VERSION "3.06 v1"

NS_ :

BS_:

BU_:

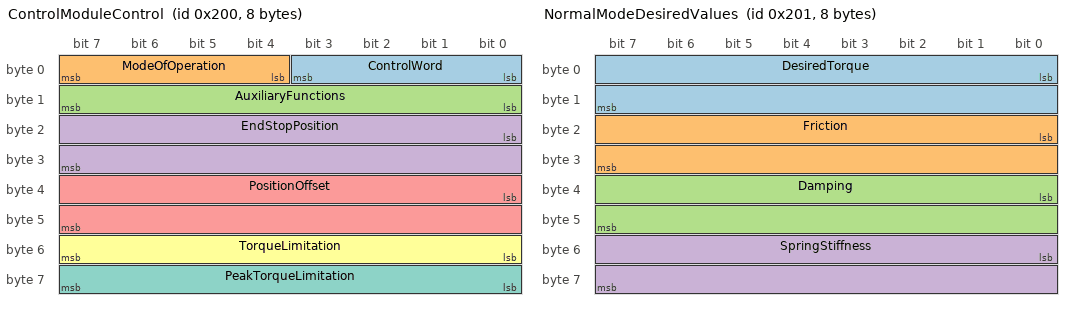
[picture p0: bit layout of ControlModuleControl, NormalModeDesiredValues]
BO_ 512 ControlModuleControl: 8 Vector__XXX
 SG_ ControlWord : 0|4@1+ (1,0) [0|15] "" Vector__XXX
 SG_ ModeOfOperation : 4|4@1+ (1,0) [1|8] "" Vector__XXX
 SG_ AuxiliaryFunctions : 8|8@1+ (1,0) [0|255] "" Vector__XXX
 SG_ EndStopPosition : 16|16@1+ (1,0) [0|1440] "°" Vector__XXX
 SG_ PositionOffset : 32|16@1- (1,0) [-359|359] "°" Vector__XXX
 SG_ TorqueLimitation : 48|8@1+ (1,0) [0|255] "%" Vector__XXX
 SG_ PeakTorqueLimitation : 56|8@1+ (1,0) [0|100] "%" Vector__XXX

BO_ 513 NormalModeDesiredValues: 8 Vector__XXX
 SG_ DesiredTorque : 0|16@1- (0.001,0) [-32.768|32.767] "Nm" Vector__XXX
 SG_ Friction : 16|16@1+ (1,0) [0|5000] "mNm" Vector__XXX
 SG_ Damping : 32|16@1+ (1,0) [0|500] "mNm/rpm" Vector__XXX
 SG_ SpringStiffness : 48|16@1+ (1,0) [0|2500] "mNm/°" Vector__XXX

BO_ 514 BasicModeDesiredValues: 2 Vector__XXX
 SG_ DesiredTorque : 0|16@1- (0.001,0) [-32.768|32.767] "Nm" Vector__XXX

BO_ 522 DigitalOutputValues: 2 Vector__XXX
 SG_ DigitalOutput : 0|3@1+ (1,0) [0|7] "" Vector__XXX

BO_ 523 AbsolutePosition: 2 Vector__XXX
 SG_ AbsolutePosition : 0|16@1- (0.1,0) [-1440|1440] "°" Vector__XXX

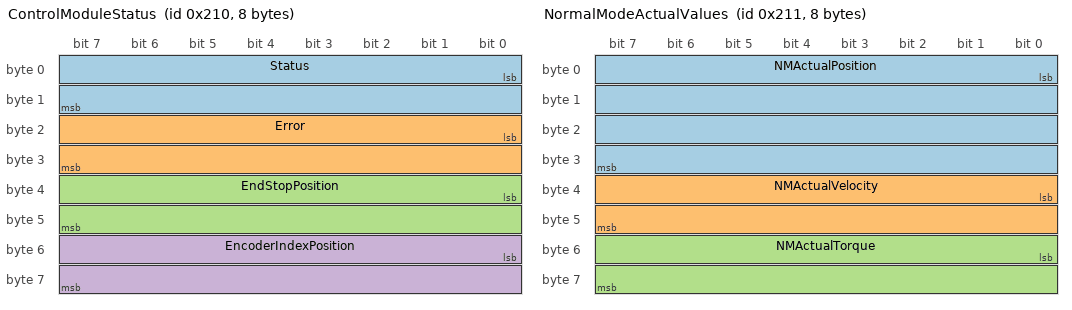
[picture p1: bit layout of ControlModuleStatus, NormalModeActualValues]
BO_ 528 ControlModuleStatus: 8 Vector__XXX
 SG_ Status : 0|16@1+ (1,0) [0|65535] "" Vector__XXX
 SG_ Error : 16|16@1+ (1,0) [0|65535] "" Vector__XXX
 SG_ EndStopPosition : 32|16@1+ (1,0) [0|1440] "°" Vector__XXX
 SG_ EncoderIndexPosition : 48|16@1- (1,0) [-359|359] "°" Vector__XXX

BO_ 529 NormalModeActualValues: 8 Vector__XXX
 SG_ NMActualPosition : 0|32@1- (1,0) [-2147483648|2147483647] "inc" Vector__XXX
 SG_ NMActualVelocity : 32|16@1- (1,0) [-32768|32767] "rpm" Vector__XXX
 SG_ NMActualTorque : 48|16@1- (0.001,0) [-32.768|32.767] "Nm" Vector__XXX

BO_ 530 BasicModeActualValues: 4 Vector__XXX
 SG_ BMActualPosition : 0|32@1- (1,0) [-2147483648|2147483647] "inc" Vector__XXX

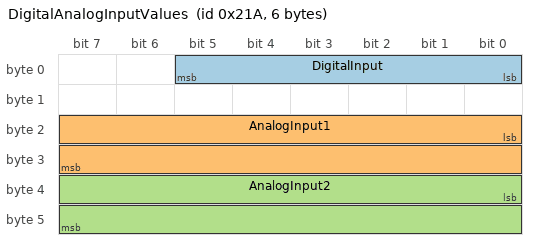
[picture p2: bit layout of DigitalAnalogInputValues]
BO_ 538 DigitalAnalogInputValues: 6 Vector__XXX
 SG_ DigitalInput : 0|6@1+ (1,0) [0|63] "" Vector__XXX
 SG_ AnalogInput1 : 16|16@1+ (1,0) [0|1023] "" Vector__XXX
 SG_ AnalogInput2 : 32|16@1+ (1,0) [0|1023] "" Vector__XXX

BO_ 539 AbsolutePositionResponse: 2 Vector__XXX
 SG_ AbsolutePosition : 0|16@1- (0.1,0) [-1440|1440] "°" Vector__XXX

VAL_ 512 ControlWord 0 "SWITCH_OFF" 2 "SWITCH_READY" 4 "SWITCH_ON" 15 "QUIT_ERROR" ;
VAL_ 512 ModeOfOperation 1 "Normal Mode" 2 "Basic Mode" 4 "Referencing Mode" 8 "Demonstration Mode" ;
